# CPSW_CPSW_52800000h register map
Vendor: Texas Instruments
Peripheral module from a debugger description file (folder AM261x).
Registers are 32-bit, read-write, reset 0x0 unless marked. A register's access mark holds for its fields unless they carry their own. Offsets are as the file gives them; lines under a group give offsets from that group; [hi:lo] are bit positions; {n}, {i} and the like mark numbered series; 'fields as' and 'values as' point back to an identical list; <NAME> marks a mode.

## CPSW (part 1 of 4)
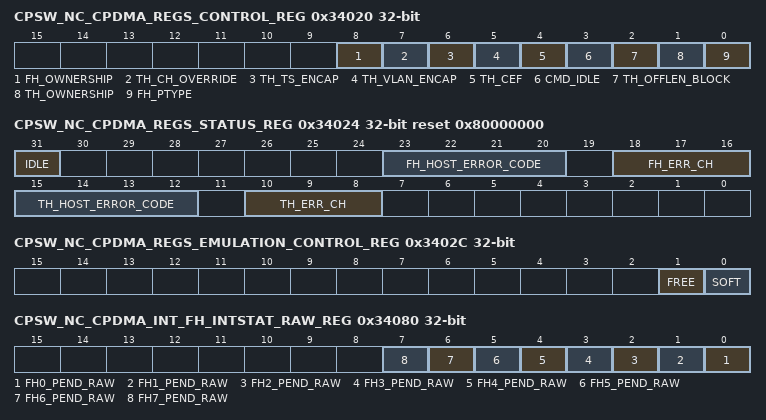
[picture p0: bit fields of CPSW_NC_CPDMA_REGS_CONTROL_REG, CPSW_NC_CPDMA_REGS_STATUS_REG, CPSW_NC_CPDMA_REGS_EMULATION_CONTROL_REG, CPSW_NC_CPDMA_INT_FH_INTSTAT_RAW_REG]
0x34020 CPSW_NC_CPDMA_REGS_CONTROL_REG — CPDMA Control Register
  [8] FH_OWNERSHIP — CPDMA FHost Ownership Write Bit Value. 0 - The CPDMA writes the FHost buffer descriptor ownership bit to zero at the end of packet processing as specified in CPPI 3.0. 1 - The CPDMA writes the FHost buffer descriptor ownership bit to one at the end of packet processing. Users who do not use the ownership mechanism can use this mode to preclude the necessity of software having to set this bit each time the buffer descriptor is used. Software must set this bit when building the packet chain.
  [7] TH_CH_OVERRIDE — CPDMA THost Channel Classification Match Override Enable 0 - The THost channel is not overridden with the ALE classification match. 1 - The THOST channel is overridden with the lower 3-bits of the ALE classification match value (if a classification match occurred).
  [6] TH_TS_ENCAP — CPDMA THost Packet Timestamp Encapsulation 0 - THost packets do not contain a 64-bit timestamp 1 - THost packets contain a 64-bit timestamp prepended to the packet data (32-bit lsword first).
  [5] TH_VLAN_ENCAP — CPDMA THost Packet VLAN Encapsulation 0 - THost packets are not VLAN encapsulated 1 - THost packets are VLAN encapsulated
  [4] TH_CEF — CPDMA THost Copy Error Frames Enable - Enables THost DMA overrun frames to be transferred to memory (up to the point of buffer overrun). The overrun error bit will be set in the frame EOP buffer descriptor. Overrun frame data will be filtered when thost_cef is not set. THost frames with other error bits set are not affected by this bit. This is related only to frames that overrun on the THost DMA due to buffer limitations. 0 - Frames containing overrun errors are filtered. 1 - Frames containing overrun errors are transferred to memory.
  [3] CMD_IDLE — CPDMA Command Idle 0 - Idle not commanded 1 - Idle Commanded (read idle in CPDMA_Status register)
  [2] TH_OFFLEN_BLOCK — CPDMA THost Offset/Length word write block 0 - Do not block the DMA writes to the THost buffer descriptor offset/buffer length word. The offset/buffer length word is written as specified in CPPI 3.0. 1 - Block all CPDMA DMA controller writes to the THost buffer descriptor offset/buffer length words during CPPI packet processing. When this bit is set, the CPDMA will never write the third word to any THost buffer descriptor.
  [1] TH_OWNERSHIP — CPDMA THost Ownership Write Bit Value 0 - The CPDMA writes the THost buffer descriptor ownership bit to zero at the end of packet processing as specified in CPPI 3.0. 1 - The CPDMA writes the THost buffer descriptor ownership bit to one at the end of packet processing. Users who do not use the ownership mechanism can use this mode to preclude the necessity of software having to set this bit each time the buffer descriptor is used. Software must set this bit when building the packet chain.
  [0] FH_PTYPE — CPDMA FHost Queue Priority Type 0 - The queue uses a round robin scheme to select the next channel. 1 - The queue uses a fixed (channel 7 highest priority) priority scheme to select the next channel.
0x34024 CPSW_NC_CPDMA_REGS_STATUS_REG ro reset 0x80000000 — CPDMA Status Register
  [31] IDLE — CPDMA Idle Status Bit - Indicates when set that the CPDMA is not transferring a packet FHost or THost.
  [23:20] FH_HOST_ERROR_CODE — CPDMA FHost Error Code - This field is set to indicate CPDMA detected FHost DMA related host errors. The host should read this field after a HOST_ERR_INT to determine the error. Host error Interrupts require hardware reset in order to recover. A zero packet length is an error, but it is not detected. 0000 - No error 0001 - SOP error 0010 - Ownership bit not set in SOP buffer 0011 - Zero Next Buffer Descriptor Pointer Without EOP 0100 - Zero Buffer Pointer 0101 - Zero Buffer Length 0110 - Packet Length Error (sum of buffers < packet length) 0111 - reserved ... 1111 - reserved
  [18:16] FH_ERR_CH — CPDMA FHost Error Channel - This field indicates the FHost channel that had a host error. 000 - The host error occurred on TX channel 0 ... 111 - The host error occurred on TX channel 7
  [15:12] TH_HOST_ERROR_CODE — CPDMA THost Error Code - This field is set to indicate CPDMA detected RX DMA related host errors. The host should read this field after a HOST_ERR_INT to determine the error. Host error Interrupts require hardware reset in order to recover. 0000 - No error 0001 - reserved 0010 - Ownership bit not set in input buffer. 0011 - reserved 0100 - Zero Buffer Pointer. 0101 - Zero buffer length on non-SOP descriptor 0110 - SOP buffer length not greater than offset ... 1111 - reserved
  [10:8] TH_ERR_CH — CPDMA THost Host Error Channel - This field indicates which THost channel had a host error. 000 - The host error occurred on THost channel 0 ... 111 - The host error occurred on RX channel 7
0x34028 CPSW_NC_CPDMA_REGS_TH_BUFFER_OFFSET_REG — CPDMA THost Buffer Offset Register
  [11:0] TH_BUFFER_OFFSET — CPDMA THost Buffer Offset Value - The thost_buffer_offset will be written by the port into each frame SOP buffer descriptor buffer_offset field. The frame data will begin after the thost_buffer_offset value of bytes. A value of 0x0 indicates that there are no unused bytes at the beginning of the data and that valid data begins on the first byte of the buffer. A value of 0xF (decimal 15) indicates that the first 15 bytes of the buffer are to be ignored by the port and that valid buffer data starts on byte 16 of the buffer. This value is used for all channels.
0x3402C CPSW_NC_CPDMA_REGS_EMULATION_CONTROL_REG — CPDMA Emulation Control Register
  [1] FREE — CPDMA Free bit
  [0] SOFT — CPDMA Soft bit
0x34080 CPSW_NC_CPDMA_INT_FH_INTSTAT_RAW_REG ro — CPDMA FHost Interrupt Status RAW
  [n] FH{n}_PEND_RAW (n=0..7) — CPDMA FHost Channel {n} Interrupt Pending RAW read (before mask)
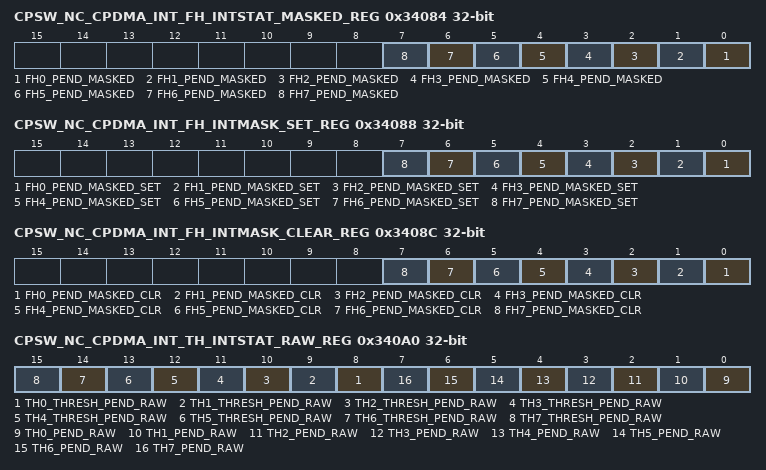
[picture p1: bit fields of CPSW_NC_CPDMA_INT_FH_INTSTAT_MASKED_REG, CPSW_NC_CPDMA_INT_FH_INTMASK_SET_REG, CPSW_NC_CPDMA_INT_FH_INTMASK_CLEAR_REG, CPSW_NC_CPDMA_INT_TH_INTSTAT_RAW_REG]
0x34084 CPSW_NC_CPDMA_INT_FH_INTSTAT_MASKED_REG ro — CPDMA FHost Interrupt Status MASKED
  [n] FH{n}_PEND_MASKED (n=0..7) — CPDMA FHost Channel {n} Interrupt Pending MASKED interrupt read
0x34088 CPSW_NC_CPDMA_INT_FH_INTMASK_SET_REG access not given — CPDMA FHost Interrupt Masked SET
  [n] FH{n}_PEND_MASKED_SET (n=0..7) — CPDMA FHost Channel {n} Interrupt Pending MASKED Set - write one to enable interrupt (access R/W1TS)
0x3408C CPSW_NC_CPDMA_INT_FH_INTMASK_CLEAR_REG access not given — CPDMA FHost Interrupt Masked CLR
  [n] FH{n}_PEND_MASKED_CLR (n=0..7) — CPDMA FHost Channel {n} Interrupt Pending MASKED Clr - write one to disable interrupt (access R/W1TC)
0x34090 CPSW_NC_CPDMA_INT_IN_VECTOR_REG ro — CPDMA DMA IN Vector
  [31:0] DMA_IN_VECTOR — The value of CPDMA_In_Vector is reset to zero, but will change to the IN_VECTOR input bus value one clock after reset is deasserted. Thereafter, this value will change to a new IN_VECTOR input value one clock after the IN_VECTOR value changes.
0x34094 CPSW_NC_CPDMA_INT_EOI_VECTOR_REG — The CPDMA_EOI_VECTOR(4:0) output bus reflects the value written to this location one VBUSP_GCLK cycle after a write to this location. The EOI_WR signal is asserted for a single clock cycle after a latency of two VBUSP_GCLK cycles when a write is performed to this location.
  [4:0] DMA_EOI_VECTOR — CPDMA DMA EOI Vector
0x340A0 CPSW_NC_CPDMA_INT_TH_INTSTAT_RAW_REG ro — CPDMA Receive Interrupt Status RAW
  [n+8] TH{n}_THRESH_PEND_RAW (n=0..7) — CPDMA Receive Channel {n} Threshold Interrupt Pending RAW read (before mask)
  [n] TH{n}_PEND_RAW (n=0..7) — CPDMA Receive Channel {n} Interrupt Pending RAW read (before mask)
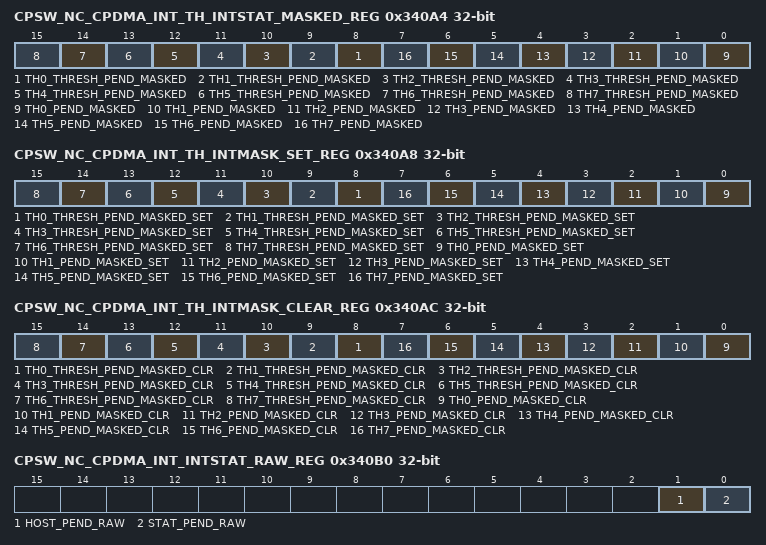
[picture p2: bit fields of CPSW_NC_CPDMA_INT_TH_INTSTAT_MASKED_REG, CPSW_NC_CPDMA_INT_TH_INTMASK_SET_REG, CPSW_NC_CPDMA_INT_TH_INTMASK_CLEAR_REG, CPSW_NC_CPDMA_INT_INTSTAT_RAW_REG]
0x340A4 CPSW_NC_CPDMA_INT_TH_INTSTAT_MASKED_REG ro — CPDMA Receive Interrupt Status MASKED
  [n+8] TH{n}_THRESH_PEND_MASKED (n=0..7) — CPDMA Receive Channel {n} Threshold Interrupt Pending MASKED read
  [n] TH{n}_PEND_MASKED (n=0..7) — CPDMA Receive Channel {n} Interrupt Pending MASKED read
0x340A8 CPSW_NC_CPDMA_INT_TH_INTMASK_SET_REG access not given — CPDMA THost Interrupt Masked SET
  [n+8] TH{n}_THRESH_PEND_MASKED_SET (n=0..7) — CPDMA THost Channel {n} Threshold Interrupt Pending SET - write one to enable interrupt (access R/W1TS)
  [n] TH{n}_PEND_MASKED_SET (n=0..7) — CPDMA THost Channel {n} Interrupt Pending SET - write one to enable interrupt (access R/W1TS)
0x340AC CPSW_NC_CPDMA_INT_TH_INTMASK_CLEAR_REG access not given — CPDMA THost Interrupt Masked CLR
  [n+8] TH{n}_THRESH_PEND_MASKED_CLR (n=0..7) — CPDMA THost Channel {n} Threshold Interrupt Pending CLR - write one to disable interrupt (access R/W1TC)
  [n] TH{n}_PEND_MASKED_CLR (n=0..7) — CPDMA THost Channel {n} Interrupt Pending CLR - write one to disable interrupt (access R/W1TC)
0x340B0 CPSW_NC_CPDMA_INT_INTSTAT_RAW_REG ro — CPDMA DMA Interrupt Status RAW
  [1] HOST_PEND_RAW — CPDMA HOST Interrupt Pending RAW - read (before mask)
  [0] STAT_PEND_RAW — CPDMA Statistics Interrupt Pending RAW - read (before mask)
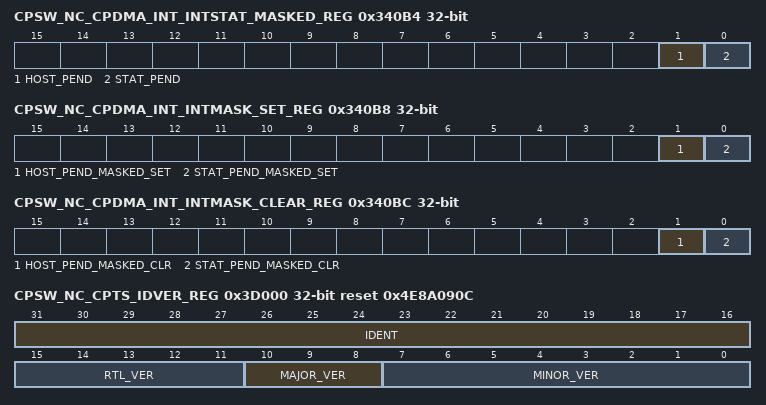
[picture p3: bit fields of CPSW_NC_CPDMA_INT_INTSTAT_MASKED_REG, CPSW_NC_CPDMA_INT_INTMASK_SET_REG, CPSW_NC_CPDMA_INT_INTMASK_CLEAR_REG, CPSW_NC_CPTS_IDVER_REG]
0x340B4 CPSW_NC_CPDMA_INT_INTSTAT_MASKED_REG ro — CPDMA DMA Interrupt Status MASKED
  [1] HOST_PEND — CPDMA HOST Interrupt Pending MASKED read
  [0] STAT_PEND — CPDMA Statistics Interrupt Pending MASKED read
0x340B8 CPSW_NC_CPDMA_INT_INTMASK_SET_REG access not given — CPDMA DMA Interrupt Status SET
  [1] HOST_PEND_MASKED_SET — CPDMA HOST Interrupt Masked SET - write one to enable interrupt (access R/W1TS)
  [0] STAT_PEND_MASKED_SET — CPDMA Statistics Interrupt Masked SET - write one to enable interrupt (access R/W1TS)
0x340BC CPSW_NC_CPDMA_INT_INTMASK_CLEAR_REG access not given — CPDMA DMA Interrupt Status CLR
  [1] HOST_PEND_MASKED_CLR — CPDMA HOST Interrupt Masked CLR - write one to disable interrupt (access R/W1TS)
  [0] STAT_PEND_MASKED_CLR — CPDMA Statistics Interrupt Masked CLR - write one to disable interrupt (access R/W1TS)
{0x340C0+4i} CPSW_NC_CPDMA_INT_TH{i}_PENDTHRESH_REG (i=0..7) — CPDMA THost Threshold Pending Register
  [7:0] TH{i}_PENDTHRESH — This field contains the threshold value for issuing threshold pending interrupts (when enabled)
{0x340E0+4i} CPSW_NC_CPDMA_INT_TH{i}_FREEBUFFER_REG (i=0..7) — CPDMA THost Free Buffer Count Register
  [15:0] TH{i}_FREEBUFFER — This field contains the count of host free buffers available. The th(0..7)_pendthresh value is compared with this field to determine if the THost threshold pending interrupt should be asseted (if enabled). This is a write to increment field. This field rolls over to zero on overflow. If THost threshold pending interrupts are used, the host must initialize this field to the number of available buffers (one register per channel). The port decrements (by the number of buffers in the frame) the associated channel register for each frame. This is a write to increment field. The host must write this field with the number of buffers that have been freed due to host processing.
{0x34200+4i} CPSW_NC_CPDMA_SRAM_FH{i}_HDP_REG (i=0..7) — CPDMA FHost Channel {i} Head Descriptor Pointer
  [31:0] FH{i}_HDP
{0x34220+4i} CPSW_NC_CPDMA_SRAM_TH{i}_HDP_REG (i=0..7) — CPDMA THost Channel {i} Head Descriptor Pointer
  [31:0] TH{i}_HDP
{0x34240+4i} CPSW_NC_CPDMA_SRAM_FH{i}_CP_REG (i=0..7) — CPDMA FHost Channel {i} Completion Pointer
  [31:0] FH{i}_CP
{0x34260+4i} CPSW_NC_CPDMA_SRAM_TH{i}_CP_REG (i=0..7) — CPDMA THost Channel {i} Completion Pointer
  [31:0] TH{i}_CP
{0x34300+4i} CPSW_NC_CPDMA_SRAM_TEST_FH{i}_HDP_REG (i=0..7) — Test CPDMA FHost Channel {i} Head Descriptor Pointer
  [31:0] TEST_FH{i}_HDP
{0x34320+4i} CPSW_NC_CPDMA_SRAM_TEST_TH{i}_HDP_REG (i=0..7) — Test CPDMA THost Channel {i} Head Descriptor Pointer
  [31:0] TEST_TH{i}_HDP
{0x34340+4i} CPSW_NC_CPDMA_SRAM_TEST_FH{i}_CP_REG (i=0..7) — Test CPDMA FHost Channel {i} Completion Pointer
  [31:0] TEST_FH{i}_CP
{0x34360+4i} CPSW_NC_CPDMA_SRAM_TEST_TH{i}_CP_REG (i=0..7) — Test CPDMA THost Channel {i} Completion Pointer
  [31:0] TEST_TH{i}_CP
0x3A000 CPSW_NC_STAT_RXGOODFRAMES_j — Total number of good frames received
  [31:0] COUNT
0x3A004 CPSW_NC_STAT_RXBROADCASTFRAMES_j — Total number of good broadcast frames received
  [31:0] COUNT
0x3A008 CPSW_NC_STAT_RXMULTICASTFRAMES_j — Total number of good multicast frames received
  [31:0] COUNT
0x3A00C CPSW_NC_STAT_RXPAUSEFRAMES_j — Total number of pause frames received
  [31:0] COUNT
0x3A010 CPSW_NC_STAT_RXCRCERRORS_j — Total number of CRC errors frames received
  [31:0] COUNT
0x3A014 CPSW_NC_STAT_RXALIGNCODEERRORS_j — Total number of alignment/code errors received
  [31:0] COUNT
0x3A018 CPSW_NC_STAT_RXOVERSIZEDFRAMES_j — Total number of oversized frames received
  [31:0] COUNT
0x3A01C CPSW_NC_STAT_RXJABBERFRAMES_j — Total number of jabber frames received
  [31:0] COUNT
0x3A020 CPSW_NC_STAT_RXUNDERSIZEDFRAMES_j — Total number of undersized frames received
  [31:0] COUNT
0x3A024 CPSW_NC_STAT_RXFRAGMENTS_j — Total number of fragmented frames received
  [31:0] COUNT
0x3A028 CPSW_NC_STAT_ALE_DROP_j — Total number of frames dropped by the ALE
  [31:0] COUNT
0x3A02C CPSW_NC_STAT_ALE_OVERRUN_DROP_j — Total number of overrun frames dropped by the ALE
  [31:0] COUNT
0x3A030 CPSW_NC_STAT_RXOCTETS_j — Total number of received bytes in good frames
  [31:0] COUNT
0x3A034 CPSW_NC_STAT_TXGOODFRAMES_j — Total number of good frames transmitted
  [31:0] COUNT
0x3A038 CPSW_NC_STAT_TXBROADCASTFRAMES_j — Total number of good broadcast frames transmitted
  [31:0] COUNT
0x3A03C CPSW_NC_STAT_TXMULTICASTFRAMES_j — Total number of good multicast frames transmitted
  [31:0] COUNT
0x3A040 CPSW_NC_STAT_TXPAUSEFRAMES_j — Total number of pause frames transmitted
  [31:0] COUNT
0x3A044 CPSW_NC_STAT_TXDEFERREDFRAMES_j — Total number of deferred frames transmitted
  [31:0] COUNT
0x3A048 CPSW_NC_STAT_TXCOLLISIONFRAMES_j — Total number of transmitted frames experiencing a collision
  [31:0] COUNT
0x3A04C CPSW_NC_STAT_TXSINGLECOLLFRAMES_j — Total number of transmitted frames experiencing a single collision
  [31:0] COUNT
0x3A050 CPSW_NC_STAT_TXMULTCOLLFRAMES_j — Total number of transmitted frames experiencing multiple collisions
  [31:0] COUNT
0x3A054 CPSW_NC_STAT_TXEXCESSIVECOLLISIONS_j — Total number of transmitted frames abandoned due to excessive collisions
  [31:0] COUNT
0x3A058 CPSW_NC_STAT_TXLATECOLLISIONS_j — Total number of transmitted frames abandoned due to a late collision
  [31:0] COUNT
0x3A05C CPSW_NC_STAT_RXIPGERROR_j — Total number of receive inter-packet gap errors (10G only)
  [31:0] COUNT
0x3A060 CPSW_NC_STAT_TXCARRIERSENSEERRORS_j — Total number of transmitted frames that experienced a carrier loss
  [31:0] COUNT
0x3A064 CPSW_NC_STAT_TXOCTETS_j — Total number of bytes in all good frames transmitted
  [31:0] COUNT
0x3A068 CPSW_NC_STAT_OCTETFRAMES64_j — Total number of 64-byte frames received and transmitted
  [31:0] COUNT
0x3A06C CPSW_NC_STAT_OCTETFRAMES65T127_j — Total number of frames of size 65 to 127 bytes received and transmitted
  [31:0] COUNT
0x3A070 CPSW_NC_STAT_OCTETFRAMES128T255_j — Total number of frames of size 128 to 255 bytes received and transmitted
  [31:0] COUNT
0x3A074 CPSW_NC_STAT_OCTETFRAMES256T511_j — Total number of frames of size 256 to 511 bytes received and transmitted
  [31:0] COUNT
0x3A078 CPSW_NC_STAT_OCTETFRAMES512T1023_j — Total number of frames of size 512 to 1023 bytes received and transmitted
  [31:0] COUNT
0x3A07C CPSW_NC_STAT_OCTETFRAMES1024TUP_j — Total number of frames of size 1024 to rx_maxlen bytes received and 1024 bytes or greater transmitted
  [31:0] COUNT
0x3A080 CPSW_NC_STAT_NETOCTETS_j — Total number of bytes received and transmitted
  [31:0] COUNT
0x3A084 CPSW_NC_STAT_RX_BOTTOM_OF_FIFO_DROP_j — Receive Bottom of FIFO Drop
  [31:0] COUNT
0x3A088 CPSW_NC_STAT_PORTMASK_DROP_j — Total number of dropped frames received due to portmask
  [31:0] COUNT
0x3A08C CPSW_NC_STAT_RX_TOP_OF_FIFO_DROP_j — Receive Top of FIFO Drop
  [31:0] COUNT
0x3A090 CPSW_NC_STAT_ALE_RATE_LIMIT_DROP_j — Total number of dropped frames due to ALE Rate Limiting
  [31:0] COUNT
0x3A094 CPSW_NC_STAT_ALE_VID_INGRESS_DROP_j — Total number of dropped frames due to ALE VID Ingress
  [31:0] COUNT
0x3A098 CPSW_NC_STAT_ALE_DA_EQ_SA_DROP_j — Total number of dropped frames due to DA=SA
  [31:0] COUNT
0x3A09C CPSW_NC_STAT_ALE_BLOCK_DROP_j — Total number of dropped frames due to ALE Block Mode
  [31:0] COUNT
0x3A0A0 CPSW_NC_STAT_ALE_SECURE_DROP_j — Total number of dropped frames due to ALE Secure Mode
  [31:0] COUNT
0x3A0A4 CPSW_NC_STAT_ALE_AUTH_DROP_j — Total number of dropped frames due to ALE Authentication
  [31:0] COUNT
0x3A0A8 CPSW_NC_STAT_ALE_UNKN_UNI_j — ALE Receive Unknown Unicast
  [31:0] COUNT
0x3A0AC CPSW_NC_STAT_ALE_UNKN_UNI_BCNT_j — ALE Receive Unknown Unicast Bytecount
  [31:0] COUNT
0x3A0B0 CPSW_NC_STAT_ALE_UNKN_MLT_j — ALE Receive Unknown Multicast
  [31:0] COUNT
0x3A0B4 CPSW_NC_STAT_ALE_UNKN_MLT_BCNT_j — ALE Receive Unknown Multicast Bytecount
  [31:0] COUNT
0x3A0B8 CPSW_NC_STAT_ALE_UNKN_BRD_j — ALE Receive Unknown Broadcast
  [31:0] COUNT
0x3A0BC CPSW_NC_STAT_ALE_UNKN_BRD_BCNT_j — ALE Receive Unknown Broadcast Bytecount
  [31:0] COUNT
0x3A0C0 CPSW_NC_STAT_ALE_POL_MATCH_j — ALE Policer Matched
  [31:0] COUNT
0x3A0C4 CPSW_NC_STAT_ALE_POL_MATCH_RED_j — ALE Policer Matched and Condition Red
  [31:0] COUNT
0x3A0C8 CPSW_NC_STAT_ALE_POL_MATCH_YELLOW_j — ALE Policer Matched and Condition Yellow
  [31:0] COUNT
0x3A0CC CPSW_NC_STAT_ALE_MULT_SA_DROP_j — ALE Multicast Source Address Drop
  [31:0] COUNT — ALE Multicast Source Address drop
0x3A0D0 CPSW_NC_STAT_ALE_DUAL_VLAN_DROP_j — ALE Dual VLAN Drop
  [31:0] COUNT — ALE Dual VLAN drop
0x3A0D4 CPSW_NC_STAT_ALE_LEN_ERROR_DROP_j — ALE Length Error Drop
  [31:0] COUNT — ALE Length Error drop
0x3A0D8 CPSW_NC_STAT_ALE_IP_NEXT_HDR_DROP_j — ALE IP Next Header Drop
  [31:0] COUNT — ALE Next Header drop
0x3A0DC CPSW_NC_STAT_ALE_IPV4_FRAG_DROP_j — ALE IPV4 Frag Drop
  [31:0] COUNT — ALE IPV4 Fragment drop
0x3A140 CPSW_NC_STAT_IET_RX_ASSEMBLY_ERROR_REG_j — IET Receive Assembly Error
  [31:0] IET_RX_ASSEMBLY_ERROR
0x3A144 CPSW_NC_STAT_IET_RX_ASSEMBLY_OK_REG_j — IET Receive Assembly Ok
  [31:0] IET_RX_ASSEMBLY_OK
0x3A148 CPSW_NC_STAT_IET_RX_SMD_ERROR_REG_j — IET Receive Smd Error
  [31:0] IET_RX_SMD_ERROR
0x3A14C CPSW_NC_STAT_IET_RX_FRAG_REG_j — IET Receive Frag
  [31:0] IET_RX_FRAG
0x3A150 CPSW_NC_STAT_IET_TX_HOLD_REG_j — IET Transmit Hold
  [31:0] IET_TX_HOLD
0x3A154 CPSW_NC_STAT_IET_TX_FRAG_REG_j — IET Transmit Frag
  [31:0] IET_TX_FRAG
0x3A17C CPSW_NC_STAT_TX_MEMORY_PROTECT_ERROR_j — Transmit Memory Protect CRC Error
  [7:0] COUNT
0x3A180 CPSW_NC_STAT_ENET_PN_TX_PRI_REG_j_k — ENET Port n PRIORITY N Packet Count
  [31:0] PN_TX_PRIN — ENET TX Priority Packet Count
0x3A1A0 CPSW_NC_STAT_ENET_PN_TX_PRI_BCNT_REG_j_k — ENET Port n PRIORITY N Packet Byte Count
  [31:0] PN_TX_PRIN_BCNT
0x3A1C0 CPSW_NC_STAT_ENET_PN_TX_PRI_DROP_REG_j_k — ENET Port n PRIORITY N Packet Drop Count
  [31:0] PN_TX_PRIN_DROP
0x3A1E0 CPSW_NC_STAT_ENET_PN_TX_PRI_DROP_BCNT_REG_j_k — ENET Port n PRIORITY N Packet Drop Byte Count
  [31:0] PN_TX_PRIN_DROP_BCNT
0x3D000 CPSW_NC_CPTS_IDVER_REG ro reset 0x4E8A090C — Identification and Version Register
  [31:16] IDENT — Identification value
  [15:11] RTL_VER — RTL version value
  [10:8] MAJOR_VER — Major version value
  [7:0] MINOR_VER — Minor version value
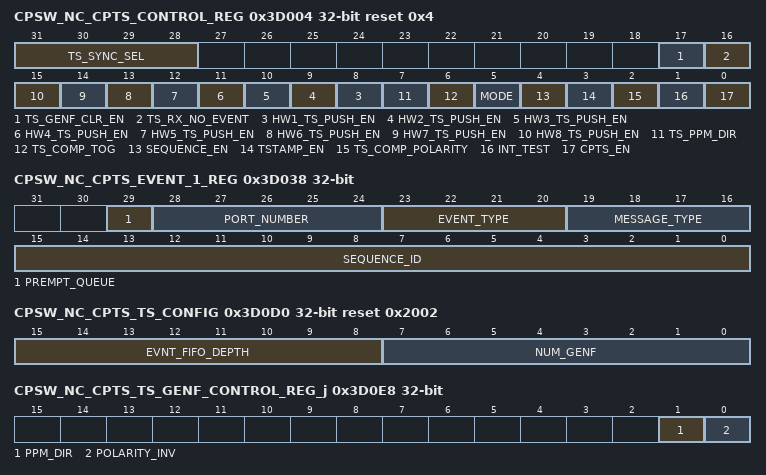
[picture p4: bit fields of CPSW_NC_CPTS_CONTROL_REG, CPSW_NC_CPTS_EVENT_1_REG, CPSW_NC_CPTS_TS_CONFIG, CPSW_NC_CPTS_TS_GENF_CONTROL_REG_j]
0x3D004 CPSW_NC_CPTS_CONTROL_REG reset 0x4 — Time Sync Control Register
  [31:28] TS_SYNC_SEL — TS_SYNC output timestamp counter bit select - 0000 - TS_SYNC disabled. 0001 - TS_SYNC is timestamp counter bit 17 0010 - TS_SYNC is timestamp counter bit 18 ... 1110 - TS_SYNC is timestamp counter bit 30 1111 - TS_SYNC is timestamp counter bit 31
  [17] TS_GENF_CLR_EN — GENF (and ESTF) Clear Enable - 0 - A TS_GENFn output is not cleared when the associated ts_genf_length[31:0] is cleared to zero. 1 - A TS_GENFn output is cleared when the associated ts_genf_length[31:0] is cleared to zero.
  [16] TS_RX_NO_EVENT — Timestamp Ethernet Receive produces no events - 0 - Ethernet receive timesync events enabled. 1 - Ethernet receive timesync events disabled.
  [n+7] HW{n}_TS_PUSH_EN (n=1..8) — Hardware push {n} enable
  [7] TS_PPM_DIR — PPM Correction Direction - 0 - Increase the time_stamp[63:0] value by the PPM value. 1 - Decrease the time_stamp[63:0] value by the PPM value.
  [6] TS_COMP_TOG — Timestamp Compare Toggle mode - 0 - TS_COMP is in non-toggle mode. 1 - TS_COMP is in toggle mode.
  [5] MODE — 64-Bit Mode - 0 - The timestamp is 32-bits with the upper 32-bits forced to zero. 1 - The timestamp is 64-bits.
  [4] SEQUENCE_EN — Sequence Enable - 0 - The timestamp value increments with the selected RFTCLK (normal operation). 1 - The timestamp for received packets is the sequence number of the received packet (first packet is 1, second packet is 2, etc). This can be used for test purposes.
  [3] TSTAMP_EN — Host Receive Timestamp Enable - 0 - Timestamps are disabled on received packets to host. 1 - Timestamps enabled on received packets to host (cpts_en must be set).
  [2] TS_COMP_POLARITY — TS_COMP Polarity 0 - TS_COMP is asserted low 1 - TS_COMP is asserted high
  [1] INT_TEST — Interrupt Test - When set, this bit allows the raw interrupt to be written to facilitate interrupt test.
  [0] CPTS_EN — Time Sync Enable - When disabled (cleared to zero), the CPTS RCLK domain is held in reset.
0x3D008 CPSW_NC_CPTS_RFTCLK_SEL_REG — RFTCLK Select Register
  [4:0] RFTCLK_SEL — Reference Clock Select - This signal is used to control an external multiplexor that selects one of up to 32 clocks for time sync reference (RFTCLK). This rftclk_sel value can be written only when the cpts_en bit and the tstamp_en bit are cleared to zero in the TS_Control register.
0x3D00C CPSW_NC_CPTS_TS_PUSH_REG wo — Time Stamp Event Push Register
  [0] TS_PUSH — Time stamp event push - When a logic high is written to this bit a time stamp event is pushed onto the event FIFO. The time stamp value is the time of the write of this register, not the time of the event read. The time stamp value can then be read on interrupt via the event registers. Software should not push a second time stamp event onto the event FIFO until the first time stamp value has been read from the event FIFO (there should be only one time stamp event in the event FIFO at any given time). This bit is write only and always reads zero.
0x3D010 CPSW_NC_CPTS_TS_LOAD_VAL_REG — Time Stamp Load Low Value Register
  [31:0] TS_LOAD_VAL — Time Stamp Load Low Value - Writing the ts_load_en bit causes ts_load[63:0] to be written into the time stamp. The time stamp value is read by initiating a time stamp push event, not by reading this register. When reading this register, the value read is not the time stamp, but is the value that was last written to this register.
0x3D014 CPSW_NC_CPTS_TS_LOAD_EN_REG wo — Time Stamp Load Enable Register
  [0] TS_LOAD_EN — Time Stamp Load - Writing a one to this bit enables the time stamp value to be written with the value in ts_load[63:0]. This bit is write only and will be cleared by the hardware after one clock. The upper 32-bits of the timestamp are forced to zero in 32-bit mode.
0x3D018 CPSW_NC_CPTS_TS_COMP_VAL_REG — Time Stamp Comparison Low Value Register
  [31:0] TS_COMP_VAL — Time Stamp Comparison Low Value - Writing a non-zero value to the TS_Comp_Length[31:0] register causes a pulse of TS_Comp_Length RCLK periods on the TS_COMP output and a comparison event when the time_stamp counter value is equivalent to ts_comp_val.
0x3D01C CPSW_NC_CPTS_TS_COMP_LEN_REG — Time Stamp Comparison Length Register
  [31:0] TS_COMP_LENGTH — Time Stamp Comparison Length - Writing a non-zero value to this field enables the time stamp comparison event and output. This value should be zero when the TS_Comp_Low and TS_Comp_High registers are written.
0x3D020 CPSW_NC_CPTS_INTSTAT_RAW_REG — Interrupt Status Register Raw
  [0] TS_PEND_RAW — TS_PEND_RAW int read (before enable). Writable when int_test = 1 A one in this bit indicates that there are one or more events in the event FIFO.
0x3D024 CPSW_NC_CPTS_INTSTAT_MASKED_REG ro — Interrupt Status Register Masked
  [0] TS_PEND — TS_PEND masked interrupt read (after enable)
0x3D028 CPSW_NC_CPTS_INT_ENABLE_REG — Interrupt Enable Register
  [0] TS_PEND_EN — TS_PEND masked interrupt enable
0x3D02C CPSW_NC_CPTS_TS_COMP_NUDGE_REG — Time Stamp Comparison Nudge Register
  [7:0] NUDGE — Timestamp Comparison Nudge Value - This two's complement number is added to the ts_comp_length[31:0] value to increase or decrease the TS_COMP length by the ts_comp_nudge amount. Only a single high or low time is adjusted and the ts_comp_nudge value is cleared to zero when the nudge has occurred.
0x3D030 CPSW_NC_CPTS_EVENT_POP_REG wo — Event Pop Register
  [0] EVENT_POP — Event Pop - When a logic high is written to this bit an event is popped off the event FIFO. The event FIFO pop occurs as part of the interrupt process after the event has been read from the Event_0-3 registers. Popping an event discards the event and causes the next event, if any, to be moved to the top of the FIFO ready to be read by software on interrupt.
0x3D034 CPSW_NC_CPTS_EVENT_0_REG ro — Event 0 Register
  [31:0] TIME_STAMP — Time Stamp lower 32-bits - The timestamp is valid for transmit, receive, and time stamp push event types. The timestamp value is not valid for counter roll event types.
0x3D038 CPSW_NC_CPTS_EVENT_1_REG ro — Event 1 Register
  [29] PREMPT_QUEUE — Prempt Queue (iet_incl = 1) - 0 - The packet was received/transmitted on the express queue. 1 - The packet was received/transmitted on the prempt queue.
  [28:24] PORT_NUMBER — Port Number - indicates the port number (encoded) of an Ethernet event or the encoded hardware timestamp number.
  [23:20] EVENT_TYPE — Time Sync Event Type - 0000 - Time Stamp Push Event 0001 - Time Stamp Rollover Event 0010 - Time Stamp Half Rollover Event 0011 - Hardware Time Stamp Push Event 0100 - Ethernet Receive Event 0101 - Ethernet Transmit Event 0110 - Time Stamp Compare Event 0111 - Host Transmit Event 1000 - reserved ... 1111 - reserved
  [19:16] MESSAGE_TYPE — Message type - The message type value that was contained in an Ethernet transmit or receive time sync packet. This field is valid only for Ethernet transmit or receive events.
  [15:0] SEQUENCE_ID — Sequence ID - The 16-bit sequence id is the value that was contained in an Ethernet transmit or receive time sync packet. This field is valid only for Ethernet transmit or receive events.
0x3D03C CPSW_NC_CPTS_EVENT_2_REG ro — Event 2 Register
  [7:0] DOMAIN — Domain - The 8-bit domain is the value that was contained in an Ethernet transmit or receive time sync packet. This field is valid only for Ethernet transmit or receive events.
0x3D040 CPSW_NC_CPTS_EVENT_3_REG ro — Event 3 Register
  [31:0] TIME_STAMP — Time Stamp - The timestamp upper 32-bits are valid for transmit, receive, and time stamp push event types. This value is zero in 32-bit mode.
0x3D044 CPSW_NC_CPTS_TS_LOAD_HIGH_VAL_REG — Time Stamp Load High Value Register
  [31:0] TS_LOAD_VAL — Time Stamp Load high Value - Writing the ts_load_en bit causes the value contained in this register (and the ts_load[63:0]) to be written into the time stamp. The time stamp value is read by initiating a time stamp push event, not by reading this register. When reading this register, the value read is not the time stamp, but is the value that was last written to this register. This value is unused in 32-bit mode.
0x3D048 CPSW_NC_CPTS_TS_COMP_HIGH_VAL_REG — Time Stamp Comparison High Value Register
  [31:0] TS_COMP_HIGH_VAL — Time Stamp Comparison High Value - Writing a non-zero value to the TS_Comp_Length[31:0] register causes a pulse of TS_Comp_Length RCLK periods on the TS_COMP output and a comparison event when the time_stamp counter value is equivalent to ts_comp_val[63:0]. This value is unused in 32-bit mode. The upper 32-bits in this register should be written before the lower 32-bits in the TS_Comp_Low register.
0x3D04C CPSW_NC_CPTS_TS_ADD_VAL_REG — TS Add Value Register
  [2:0] ADD_VAL — The ts_add_value[2:0] is added to 1 to comprise the timestamp increment value. The timestamp increment value is added to the current timestamp (time_stamp[63:0]) on each RCLK. The timestamp increment value can be adjusted by nudge and ppm also. The ts_add_val[2:0] value may be non-zero in 64-bit mode only.
0x3D050 CPSW_NC_CPTS_TS_PPM_LOW_VAL_REG — Time Stamp PPM Low Value Register
  [31:0] TS_PPM_LOW_VAL — Time Stamp PPM Low Value - The 64-bit PPM value takes effect when this low value is written. The high value should be written first. Note: There should be at least 10 clocks in between writes to the low register to ensure that the previous operation has been seen.
0x3D054 CPSW_NC_CPTS_TS_PPM_HIGH_VAL_REG — Time Stamp PPM High Value Register
  [9:0] TS_PPM_HIGH_VAL — Time Stamp PPM High Value - This value should be written first (before the low value is written). The minimum value of the ts_ppm is 0x400 (all 42 bits).
0x3D058 CPSW_NC_CPTS_TS_NUDGE_VAL_REG — Time Stamp Nudge Value Register
  [7:0] TS_NUDGE_VAL — Timestamp Nudge Value - This two's complement number is added to the time_stamp[63:0] value to increase or decrease the timestamp value by the ts_nudge amount. The ts_nudge value is cleared to zero when the nudge has occurred.
0x3D0D0 CPSW_NC_CPTS_TS_CONFIG ro reset 0x2002 — Time Stamp Configuration Read
  [15:8] EVNT_FIFO_DEPTH — This is the configured value for the depth of the event FIFO. This parameter is passed in at module generation.
  [7:0] NUM_GENF — This is the configured value for the number of GENF outputs. This parameter is passed in at module generation.
0x3D0E0 CPSW_NC_CPTS_TS_GENF_COMP_LOW_REG_j — Time Stamp Generate Function Comparison Low Value
  [31:0] COMP_LOW — GENFn comparison value lower 32-bits. This value should be written after the upper 32-bits. The ts_GENFn_comp high and low should only be written when the ts_GENFn_length value is zero.
0x3D0E4 CPSW_NC_CPTS_TS_GENF_COMP_HIGH_REG_j — Time Stamp Generate Function Comparison high Value
  [31:0] COMP_HIGH — GENFn comparison value upper 32-bits. This value should be written before the lower 32-bits are written. The ts_GENFn_comp high and low should only be written when the ts_GENFn_length value is zero.
0x3D0E8 CPSW_NC_CPTS_TS_GENF_CONTROL_REG_j — Time Stamp Generate Function Control
  [1] PPM_DIR — Generate function N PPM direction - 0 - A single RCLK is added to the generate function counter at the PPM rate which has the effect of decreasing the generate function frequency by the PPM amount. 1 - A single RCLK is subtracted from the generate function counter at the PPM rate which has the effect of increasing the generate function frequency by the PPM amount.
  [0] POLARITY_INV — Generate function N Polarity - 0 - The output TS_GENFn signal asserts high. 1 - The output TS_GENFn signal asserts low
0x3D0EC CPSW_NC_CPTS_TS_GENF_LENGTH_REG_j — Time Stamp Generate Function Length Value
  [31:0] LENGTH — GENFn length - The minimum operational value is decimal 5. Note: Software is advised to write and then read the comparison value before writing a non-zero value to the genf length to ensure that the comparison value is synchronized across the boundary before the length.
0x3D0F0 CPSW_NC_CPTS_TS_GENF_PPM_LOW_REG_j — Time Stamp Generate Function PPM Low Value
  [31:0] PPM_LOW — GENFn PPM Low Value - The 64-bit PPM value takes effect when this low value is written. The high value should be written first.
0x3D0F4 CPSW_NC_CPTS_TS_GENF_PPM_HIGH_REG_j — Time Stamp Generate Function PPM High Value
  [9:0] PPM_HIGH — GENFn PPM High Value - This value should be written first (before the low value is written).
0x3D0F8 CPSW_NC_CPTS_TS_GENF_NUDGE_REG_j — Time Stamp Generate Function Nudge Value
  [7:0] NUDGE — GENFn Nudge Value - This two's complement number is added to the generate counter value to increase or decrease the length by the ts_genfN_nudge amount. Only a single high or low time is adjusted and the ts_genfN_nudge value is cleared to zero when the nudge has occurred.
0x3D200 CPSW_NC_CPTS_TS_ESTF_COMP_LOW_REG_j — Time Stamp ESTF Generate Function Comparison Low Value
  [31:0] COMP_LOW — ESTFn comparison value lower 32-bits. This value should be written after the upper 32-bits. The ts_ESTFn_comp high and low should only be written when the ts_ESTFn_length value is zero.
0x3D204 CPSW_NC_CPTS_TS_ESTF_COMP_HIGH_REG_j — Time Stamp ESTF Generate Function Comparison high Value
  [31:0] COMP_HIGH — ESTFn comparison value upper 32-bits. This value should be written before the lower 32-bits are written. The ts_ESTFn_comp high and low should only be written when the ts_ESTFn_length value is zero.
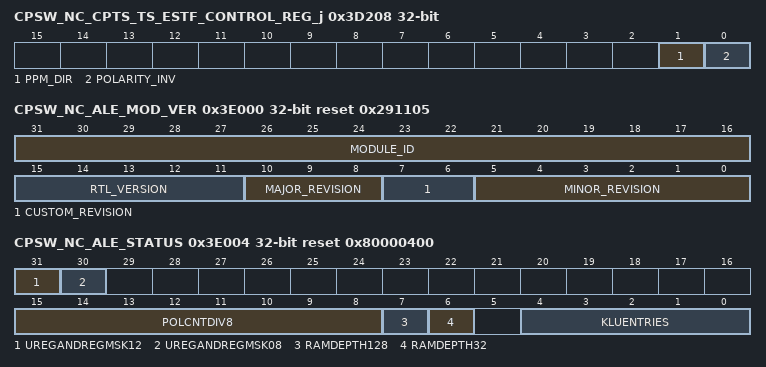
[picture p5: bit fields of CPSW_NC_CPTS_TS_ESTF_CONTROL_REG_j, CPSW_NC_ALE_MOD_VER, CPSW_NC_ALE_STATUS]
0x3D208 CPSW_NC_CPTS_TS_ESTF_CONTROL_REG_j — Time Stamp ESTF Generate Function Control
  [1] PPM_DIR — Generate function N PPM direction - 0 - A single RCLK is added to the generate function counter at the PPM rate which has the effect of decreasing the generate function frequency by the PPM amount. 1 - A single RCLK is subtracted from the generate function counter at the PPM rate which has the effect of increasing the generate function frequency by the PPM amount.
  [0] POLARITY_INV — Generate function N Polarity - 0 - The output TS_ESTFn signal asserts low. 1 - The output TS_ESTFn signal asserts high.
0x3D20C CPSW_NC_CPTS_TS_ESTF_LENGTH_REG_j — Time Stamp ESTF Generate Function Length Value
  [31:0] LENGTH — ESTFn length - The minimum operational value is decimal 5. Note: Software is advised to write and then read the comparison value before writing a non-zero value to the genf length to ensure that the comparison value is synchronized across the boundary before the length.
0x3D210 CPSW_NC_CPTS_TS_ESTF_PPM_LOW_REG_j — Time Stamp ESTF Generate Function PPM Low Value
  [31:0] PPM_LOW — ESTFn PPM Low Value - The 64-bit PPM value takes effect when this low value is written. The high value should be written first.
0x3D214 CPSW_NC_CPTS_TS_ESTF_PPM_HIGH_REG_j — Time Stamp ESTF Generate Function PPM High Value
  [9:0] PPM_HIGH — ESTFn PPM High Value - This value should be written first (before the low value is written).
0x3D218 CPSW_NC_CPTS_TS_ESTF_NUDGE_REG_j — Time Stamp ESTF Generate Function Nudge Value
  [7:0] NUDGE — ESTFn Nudge Value - This two's complement number is added to the generate counter value to increase or decrease the length by the ts_estfN_nudge amount. Only a single high or low time is adjusted and the ts_estfN_nudge value is cleared to zero when the nudge has occurred.
0x3E000 CPSW_NC_ALE_MOD_VER ro reset 0x291105 — The Module and Version Register identifies the module identifier and revision of the ALE_3g512nie module.
  [31:16] MODULE_ID — ALE_3g512nie module ID.
  [15:11] RTL_VERSION
  [10:8] MAJOR_REVISION
  [7:6] CUSTOM_REVISION
  [5:0] MINOR_REVISION
0x3E004 CPSW_NC_ALE_STATUS ro reset 0x80000400 — The ALE status provides information on the ALE configuration and state. The ramdepth is used to determine how IPv6 entries are stored in the table. IPv6 entries are stored in two entries where IPv6 Entry Hi is designated by the odd slice index and Lo is designated by the even slice index. The slice index is above the ram depth like {SliceIndex,RamIndex}. So, for a 64 deep RAM index of 0x005, the Hi portion of the IPv6 entry is located at 0x005|(0x040) and the Lo portion is located at 0x005 & (~0x040).
  [31] UREGANDREGMSK12 — When set, the unregistered multicast field is a mask versus an index on 12 bit boundary in the ALE table.
  [30] UREGANDREGMSK08 — When set, the unregistered multicast field is a mask versus an index on 8 bit boundary in the ALE table.
  [15:8] POLCNTDIV8 — This is the number of Classifiers the ALE implements divided by 8. A value of 4 indicates 32 policer engines total.
  [7] RAMDEPTH128 — The number of ALE entries per slice of the table when this is set it indicates the depth is 128 if both ramdepth128 and ramdepth32 are zero the depth is 64.
  [6] RAMDEPTH32 — The number of ALE entries per slice of the table when this is set it indicates the depth is 32 if both ramdepth128 and ramdepth32 are zero the depth is 64.
  [4:0] KLUENTRIES — This is the number of table entries total divided by 1024. A value of 1 indicates 1024 table entries. A value of 8 indicates 8192 table entries.
